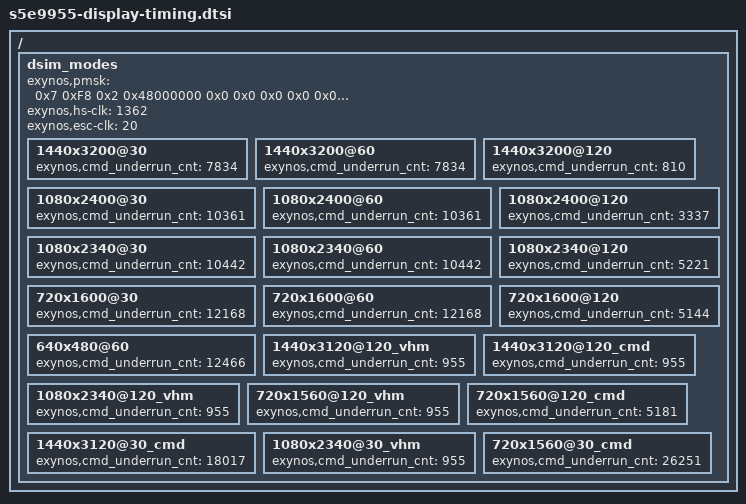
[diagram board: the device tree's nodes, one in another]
// SPDX-License-Identifier: GPL-2.0-only
/*
 * SAMSUNG EXYNOS SoC device tree source
 *
 * Copyright (c) 2019 Samsung Electronics Co., Ltd.
 *		http://www.samsung.com
 *
 */

/ {
	dsim_modes: dsim_modes {
		/*
		 * exynos,property can be declared in both dsim_modes node and
		 * the below nodes. The exynos,property of parent node is inherited to
		 * child node only if child node don't have exynos,property.
		 */
		exynos,pmsk = <
			0x7 0xF8 0x2 0x48000000	/* p m s f */
			0x0 0x0 0x0 0x0		/* mfr mrr sel_pf icp */
			0x0 0x0 0x0 0x0		/* afc_enb extafc feed_en fsel */
			0x0 0x0			/* fout_mask rsel */
			>;
		exynos,hs-clk = <1362>;
		exynos,esc-clk = <20>;
		1440x3200@30 {
		        exynos,cmd_underrun_cnt = <7834>;
		};
		1440x3200@60 {
		        exynos,cmd_underrun_cnt = <7834>;
		};
		1440x3200@120 {
		        exynos,cmd_underrun_cnt = <810>;
		};
		1080x2400@30 {
		        exynos,cmd_underrun_cnt = <10361>;
		};
		1080x2400@60 {
		        exynos,cmd_underrun_cnt = <10361>;
		};
		1080x2400@120 {
		        exynos,cmd_underrun_cnt = <3337>;
		};
		1080x2340@30 {
		        exynos,cmd_underrun_cnt = <10442>;
		};
		1080x2340@60 {
		        exynos,cmd_underrun_cnt = <10442>;
		};
		1080x2340@120 {
		        exynos,cmd_underrun_cnt = <5221>;
		};
		720x1600@30 {
		        exynos,cmd_underrun_cnt = <12168>;
		};
		720x1600@60 {
		        exynos,cmd_underrun_cnt = <12168>;
		};
		720x1600@120 {
		        exynos,cmd_underrun_cnt = <5144>;
		};
		/* for zebu emulator */
		640x480@60 {
		        exynos,cmd_underrun_cnt = <12466>;
		};
		/* for s6e3haf */
		1440x3120@120_vhm {
		        exynos,cmd_underrun_cnt = <955>;
		};
		1440x3120@120_cmd {
		        exynos,cmd_underrun_cnt = <955>;
		};
		1080x2340@120_vhm {
		        exynos,cmd_underrun_cnt = <955>;
		};
		720x1560@120_vhm {
		        exynos,cmd_underrun_cnt = <955>;
		};
		720x1560@120_cmd {
		        exynos,cmd_underrun_cnt = <5181>;
		};
		1440x3120@30_cmd {
		        exynos,cmd_underrun_cnt = <18017>;
		};
		1080x2340@30_vhm {
		        exynos,cmd_underrun_cnt = <955>;
		};
		720x1560@30_cmd {
		        exynos,cmd_underrun_cnt = <26251>;
		};
	};
};
